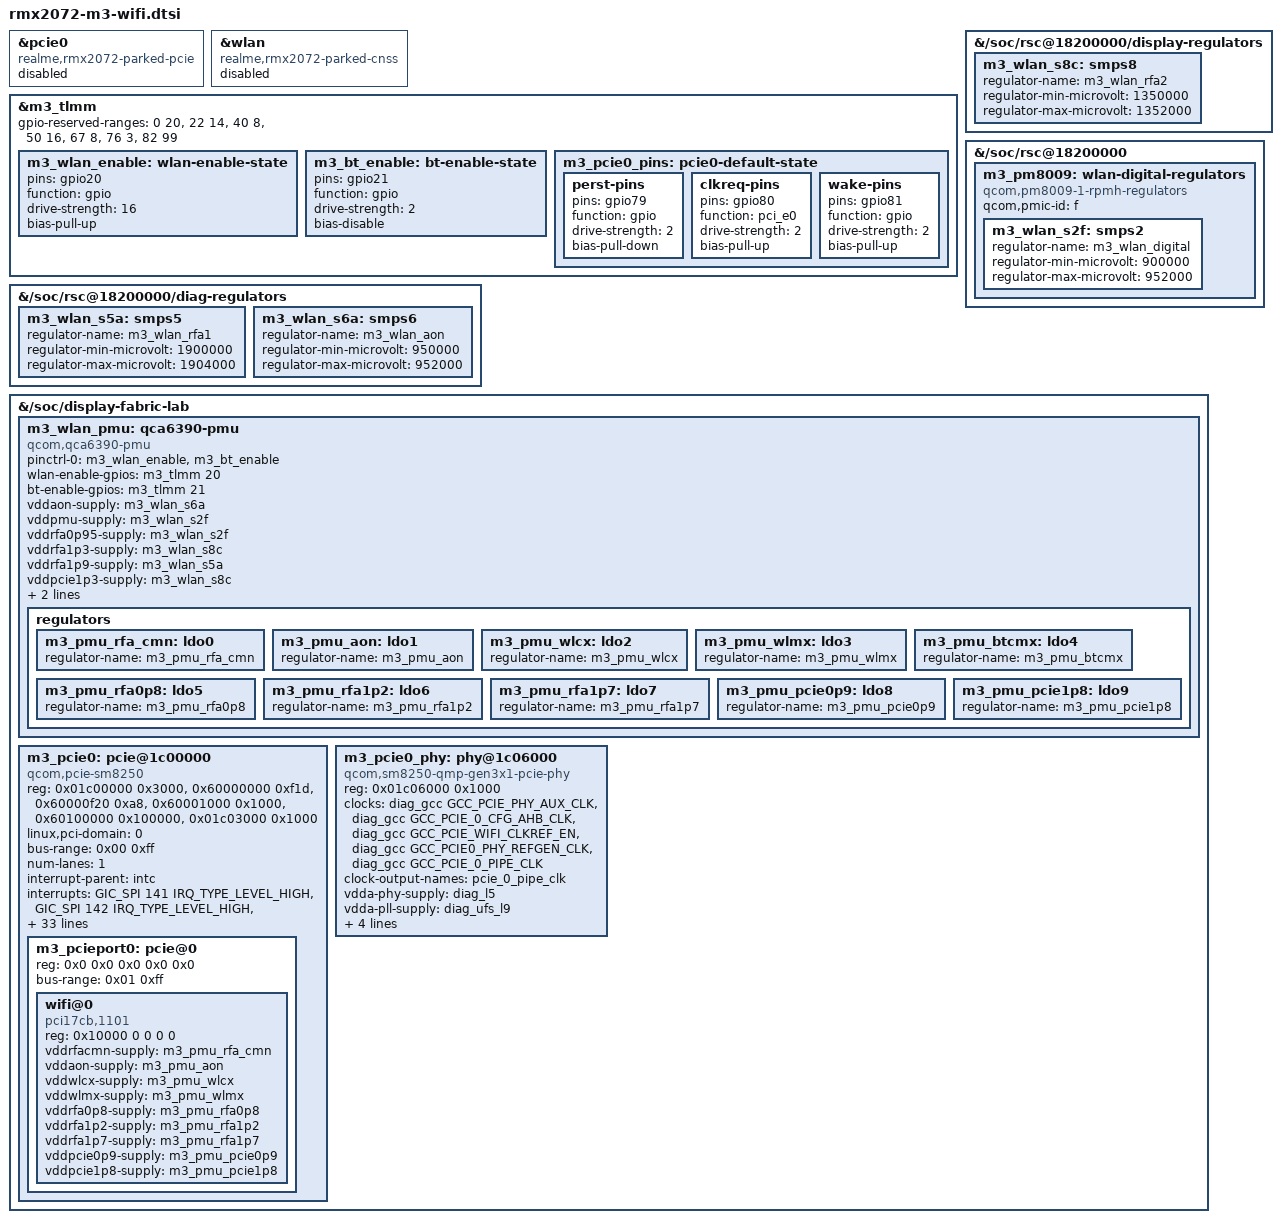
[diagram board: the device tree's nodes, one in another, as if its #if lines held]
// SPDX-License-Identifier: GPL-2.0-only
// Native PCIe resources: ACK ecdaacc9, SM8250 PCIe0/GEN3x1.
// Board wiring: realme 24a15224, 20607 kona.dtsi/kona-pcie.dtsi.
// This board uses PM8009 S2 for WLAN DIG; do not substitute elish's S6A.
// Initial acceptance is PCI identity; no foreign board calibration is supplied.
&pcie0 { status = "disabled"; compatible = "realme,rmx2072-parked-pcie"; };
&wlan { status = "disabled"; compatible = "realme,rmx2072-parked-cnss"; };
&m3_tlmm {
    gpio-reserved-ranges = <0 20>, <22 14>, <40 8>, <50 16>, <67 8>, <76 3>, <82 99>;
    m3_wlan_enable: wlan-enable-state {
        pins = "gpio20"; function = "gpio"; drive-strength = <16>; bias-pull-up;
    };
    m3_bt_enable: bt-enable-state {
        pins = "gpio21"; function = "gpio"; drive-strength = <2>; bias-disable;
    };
    m3_pcie0_pins: pcie0-default-state {
        perst-pins { pins = "gpio79"; function = "gpio"; drive-strength = <2>; bias-pull-down; };
        clkreq-pins { pins = "gpio80"; function = "pci_e0"; drive-strength = <2>; bias-pull-up; };
        wake-pins { pins = "gpio81"; function = "gpio"; drive-strength = <2>; bias-pull-up; };
    };
};
&{/soc/rsc@18200000/diag-regulators} {
    m3_wlan_s5a: smps5 {
        regulator-name = "m3_wlan_rfa1";
        regulator-min-microvolt = <1900000>;
        regulator-max-microvolt = <1904000>;
    };
    m3_wlan_s6a: smps6 {
        regulator-name = "m3_wlan_aon";
        regulator-min-microvolt = <950000>;
        regulator-max-microvolt = <952000>;
    };
};
&{/soc/rsc@18200000/display-regulators} {
    m3_wlan_s8c: smps8 {
        regulator-name = "m3_wlan_rfa2";
        regulator-min-microvolt = <1350000>;
        regulator-max-microvolt = <1352000>;
    };
};
&{/soc/rsc@18200000} {
    m3_pm8009: wlan-digital-regulators {
        compatible = "qcom,pm8009-1-rpmh-regulators";
        qcom,pmic-id = "f";
        m3_wlan_s2f: smps2 {
            regulator-name = "m3_wlan_digital";
            // SM8250 PM8009-1: ACK selectors are 900 + n*16 mV.
            // Use the upstream RB5 constraint, not downstream's direct
            // 950 mV RPMh vote: 950..952 contains no ACK selector.
            regulator-min-microvolt = <900000>;
            regulator-max-microvolt = <952000>;
        };
    };
};
#ifdef RMX2072_M3_STAGED
&{/soc/display-fabric-lab} {
#else
&{/soc} {
#endif
    m3_wlan_pmu: qca6390-pmu {
        compatible = "qcom,qca6390-pmu";
        pinctrl-names = "default";
        pinctrl-0 = <&m3_wlan_enable &m3_bt_enable>;
        wlan-enable-gpios = <&m3_tlmm 20 GPIO_ACTIVE_HIGH>;
        bt-enable-gpios = <&m3_tlmm 21 GPIO_ACTIVE_HIGH>;
        vddaon-supply = <&m3_wlan_s6a>;
        vddpmu-supply = <&m3_wlan_s2f>;
        vddrfa0p95-supply = <&m3_wlan_s2f>;
        vddrfa1p3-supply = <&m3_wlan_s8c>;
        vddrfa1p9-supply = <&m3_wlan_s5a>;
        vddpcie1p3-supply = <&m3_wlan_s8c>;
        vddpcie1p9-supply = <&m3_wlan_s5a>;
        vddio-supply = <&diag_ufs_s4>;
        regulators {
            m3_pmu_rfa_cmn: ldo0 { regulator-name = "m3_pmu_rfa_cmn"; };
            m3_pmu_aon: ldo1 { regulator-name = "m3_pmu_aon"; };
            m3_pmu_wlcx: ldo2 { regulator-name = "m3_pmu_wlcx"; };
            m3_pmu_wlmx: ldo3 { regulator-name = "m3_pmu_wlmx"; };
            m3_pmu_btcmx: ldo4 { regulator-name = "m3_pmu_btcmx"; };
            m3_pmu_rfa0p8: ldo5 { regulator-name = "m3_pmu_rfa0p8"; };
            m3_pmu_rfa1p2: ldo6 { regulator-name = "m3_pmu_rfa1p2"; };
            m3_pmu_rfa1p7: ldo7 { regulator-name = "m3_pmu_rfa1p7"; };
            m3_pmu_pcie0p9: ldo8 { regulator-name = "m3_pmu_pcie0p9"; };
            m3_pmu_pcie1p8: ldo9 { regulator-name = "m3_pmu_pcie1p8"; };
        };
    };
m3_pcie0: pcie@1c00000 {
			compatible = "qcom,pcie-sm8250";
			reg = <0x01c00000 0x3000>,
			      <0x60000000 0xf1d>,
			      <0x60000f20 0xa8>,
			      <0x60001000 0x1000>,
			      <0x60100000 0x100000>,
			      <0x01c03000 0x1000>;
			reg-names = "parf", "dbi", "elbi", "atu", "config", "mhi";
			device_type = "pci";
			linux,pci-domain = <0>;
			bus-range = <0x00 0xff>;
			num-lanes = <1>;

			#address-cells = <3>;
			#size-cells = <2>;

			ranges = <0x01000000 0x0 0x00000000 0x60200000 0x0 0x100000>,
				 <0x02000000 0x0 0x60300000 0x60300000 0x0 0x3d00000>;

			interrupt-parent = <&intc>;
            interrupts = <GIC_SPI 141 IRQ_TYPE_LEVEL_HIGH>,
				     <GIC_SPI 142 IRQ_TYPE_LEVEL_HIGH>,
				     <GIC_SPI 143 IRQ_TYPE_LEVEL_HIGH>,
				     <GIC_SPI 144 IRQ_TYPE_LEVEL_HIGH>,
				     <GIC_SPI 145 IRQ_TYPE_LEVEL_HIGH>,
				     <GIC_SPI 146 IRQ_TYPE_LEVEL_HIGH>,
				     <GIC_SPI 147 IRQ_TYPE_LEVEL_HIGH>,
				     <GIC_SPI 148 IRQ_TYPE_LEVEL_HIGH>,
				     <GIC_SPI 140 IRQ_TYPE_LEVEL_HIGH>;
			interrupt-names = "msi0",
					  "msi1",
					  "msi2",
					  "msi3",
					  "msi4",
					  "msi5",
					  "msi6",
					  "msi7",
					  "global";
			#interrupt-cells = <1>;
			interrupt-map-mask = <0 0 0 0x7>;
			interrupt-map = <0 0 0 1 &intc GIC_SPI 149 IRQ_TYPE_LEVEL_HIGH>, /* int_a */
					<0 0 0 2 &intc GIC_SPI 150 IRQ_TYPE_LEVEL_HIGH>, /* int_b */
					<0 0 0 3 &intc GIC_SPI 151 IRQ_TYPE_LEVEL_HIGH>, /* int_c */
					<0 0 0 4 &intc GIC_SPI 152 IRQ_TYPE_LEVEL_HIGH>; /* int_d */

			clocks = <&diag_gcc GCC_PCIE_0_PIPE_CLK>,
				 <&diag_gcc GCC_PCIE_0_AUX_CLK>,
				 <&diag_gcc GCC_PCIE_0_CFG_AHB_CLK>,
				 <&diag_gcc GCC_PCIE_0_MSTR_AXI_CLK>,
				 <&diag_gcc GCC_PCIE_0_SLV_AXI_CLK>,
				 <&diag_gcc GCC_PCIE_0_SLV_Q2A_AXI_CLK>,
				 <&diag_gcc GCC_AGGRE_NOC_PCIE_TBU_CLK>,
				 <&diag_gcc GCC_DDRSS_PCIE_SF_TBU_CLK>;
			clock-names = "pipe",
				      "aux",
				      "cfg",
				      "bus_master",
				      "bus_slave",
				      "slave_q2a",
				      "tbu",
				      "ddrss_sf_tbu";

			iommu-map = <0x0   &apps_smmu 0x1c00 0x1>,
				    <0x100 &apps_smmu 0x1c01 0x1>;

			resets = <&diag_gcc GCC_PCIE_0_BCR>;
			reset-names = "pci";

			power-domains = <&diag_gcc PCIE_0_GDSC>;

			phys = <&m3_pcie0_phy>;
			phy-names = "pciephy";

			perst-gpios = <&m3_tlmm 79 GPIO_ACTIVE_LOW>;
			wake-gpios = <&m3_tlmm 81 GPIO_ACTIVE_HIGH>;

			pinctrl-names = "default";
			pinctrl-0 = <&m3_pcie0_pins>;
			dma-coherent;

			status = "okay";

			m3_pcieport0: pcie@0 {
				device_type = "pci";
				reg = <0x0 0x0 0x0 0x0 0x0>;
				bus-range = <0x01 0xff>;

				#address-cells = <3>;
				#size-cells = <2>;
				ranges;
			};
		};

		m3_pcie0_phy: phy@1c06000 {
			compatible = "qcom,sm8250-qmp-gen3x1-pcie-phy";
			reg = <0x01c06000 0x1000>;

			clocks = <&diag_gcc GCC_PCIE_PHY_AUX_CLK>,
				 <&diag_gcc GCC_PCIE_0_CFG_AHB_CLK>,
				 <&diag_gcc GCC_PCIE_WIFI_CLKREF_EN>,
				 <&diag_gcc GCC_PCIE0_PHY_REFGEN_CLK>,
				 <&diag_gcc GCC_PCIE_0_PIPE_CLK>;
			clock-names = "aux",
				      "cfg_ahb",
				      "ref",
				      "refgen",
				      "pipe";

			clock-output-names = "pcie_0_pipe_clk";
            vdda-phy-supply = <&diag_l5>;
            vdda-pll-supply = <&diag_ufs_l9>;
			#clock-cells = <0>;

			#phy-cells = <0>;

			resets = <&diag_gcc GCC_PCIE_0_PHY_BCR>;
			reset-names = "phy";

			assigned-clocks = <&diag_gcc GCC_PCIE0_PHY_REFGEN_CLK>;
			assigned-clock-rates = <100000000>;

			status = "okay";
		};

};
&m3_pcieport0 {
    wifi@0 {
        compatible = "pci17cb,1101";
        reg = <0x10000 0 0 0 0>;
        vddrfacmn-supply = <&m3_pmu_rfa_cmn>;
        vddaon-supply = <&m3_pmu_aon>;
        vddwlcx-supply = <&m3_pmu_wlcx>;
        vddwlmx-supply = <&m3_pmu_wlmx>;
        vddrfa0p8-supply = <&m3_pmu_rfa0p8>;
        vddrfa1p2-supply = <&m3_pmu_rfa1p2>;
        vddrfa1p7-supply = <&m3_pmu_rfa1p7>;
        vddpcie0p9-supply = <&m3_pmu_pcie0p9>;
        vddpcie1p8-supply = <&m3_pmu_pcie1p8>;
    };
};
